# CPSW0_NUSS_ALE register map
Vendor: Texas Instruments
Peripheral module from a debugger description file (folder J7VCL).
Registers are 32-bit, read-write, reset values left out (the file's numbers can be read two ways) unless marked. A register's access mark holds for its fields unless they carry their own. Offsets are as the file gives them; lines under a group give offsets from that group; [hi:lo] are bit positions; {n}, {i} and the like mark numbered series; 'fields as' and 'values as' point back to an identical list; <NAME> marks a mode.

## CPSW0_NUSS_ALE
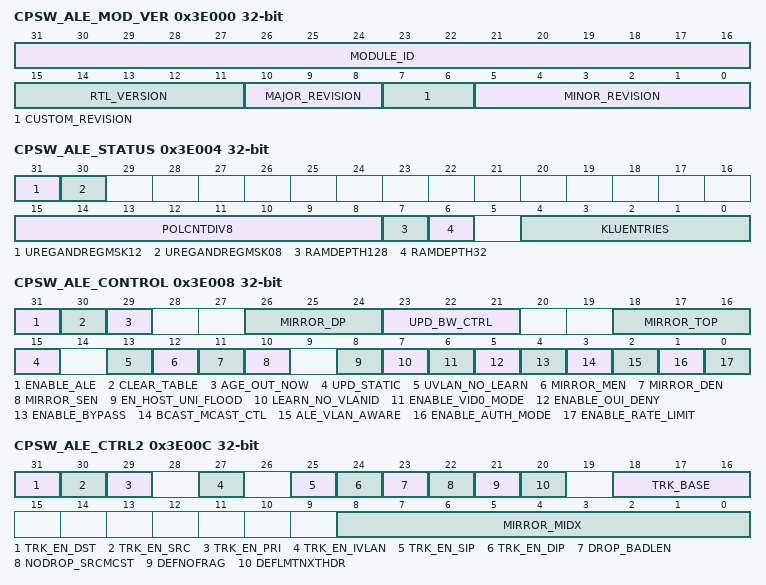
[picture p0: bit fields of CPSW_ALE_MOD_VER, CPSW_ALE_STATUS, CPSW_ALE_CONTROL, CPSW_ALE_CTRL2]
0x3E000 CPSW_ALE_MOD_VER ro — The Module and Version Register identifies the module identifier and revision of the ALE module.
  [31:16] MODULE_ID — ALE module ID.
  [15:11] RTL_VERSION
  [10:8] MAJOR_REVISION
  [7:6] CUSTOM_REVISION
  [5:0] MINOR_REVISION
0x3E004 CPSW_ALE_STATUS ro — The ALE status provides information on the ALE configuration and state. The RAMDEPTH is used to determine how IPv6 entries are stored in the table. IPv6 entries are stored in two entries where IPv6 Entry Hi is designated by the odd slice index and Lo is designated by the even slice index. The slice index is above the ram depth like {SlixeIndex,RamIndex}. So for a 64 deep RAM index of 0x005, the Hi portion of the IPv6 entry is located at 0x005|0x040 and the Lo portion is located at 0x005&(~0x040).
  [31] UREGANDREGMSK12 — When set, the unregistered multicast field is a mask versus an index on 12 bit boundary in the ALE table.
  [30] UREGANDREGMSK08 — When set, the unregistered multicast field is a mask versus an index on 8 bit boundary in the ALE table.
  [15:8] POLCNTDIV8 — This is the number of policer engines the ALE implements divided by 8.
  [7] RAMDEPTH128 — The number of ALE entries per slice of the table when this is set it indicates the depth is 128 if both ramdepth128 and ramdepth32 are zero the depth is 64.
  [6] RAMDEPTH32 — The number of ALE entries per slice of the table when this is set it indicates the depth is 32 if both ramdepth128 and ramdepth32 are zero the depth is 64.
  [4:0] KLUENTRIES — This is the number of table entries total divided by 1024.
0x3E008 CPSW_ALE_CONTROL — The ALE Control Register is used to set the ALE modes used for all ports.
  [31] ENABLE_ALE
  [30] CLEAR_TABLE — Clear ALE address table. Setting this bit causes the ALE hardware to write all table bit values to zero.
  [29] AGE_OUT_NOW — Age Out Address Table Now. Setting this bit causes the ALE hardware to remove (free up) any ageable table entry that does not have a set touch bit.
  [26:24] MIRROR_DP — Mirror Destination Port. This field defines the port to which destination traffic destined will be duplicated.
  [23:21] UPD_BW_CTRL — The UPD_BW_CTRL field allows for up to 8 times the rate in which adds, updates, touches, writes, and aging updates can occur.
  [18:16] MIRROR_TOP — Mirror To Port. This field defines the destination port for the mirror traffic.
  [15] UPD_STATIC — Update Static Entries. A static Entry is an entry that is not agable.
  [13] UVLAN_NO_LEARN — Unknown VLAN No Learn. This field when set will prevent source addresses of unknown VLAN IDs from being automatically added into the look up table if learning is enabled.
  [12] MIRROR_MEN — Mirror Match Entry Enable. This field enables the match mirror option.
  [11] MIRROR_DEN — Mirror Destination Port Enable. This field enables the destination port mirror option.
  [10] MIRROR_SEN — Mirror Source Port Enable. This field enables the source port mirror option.
  [8] EN_HOST_UNI_FLOOD — Unknown unicast packets flood to host.
  [7] LEARN_NO_VLANID — Learn No VID.
  [6] ENABLE_VID0_MODE — Enable VLAN ID = 0 Mode.
  [5] ENABLE_OUI_DENY — Enable OUI Deny Mode. When set, any packet with a non-matching OUI source address will be dropped to the host unless the packet destination address matches a supervisory destination address table entry.
  [4] ENABLE_BYPASS — ALE Bypass. When set, packets received on non-host ports are sent to the host.
  [3] BCAST_MCAST_CTL — Rate Limit Transmit mode.
  [2] ALE_VLAN_AWARE — ALE VLAN Aware. Determines how traffic is forwarded using VLAN rules.
  [1] ENABLE_AUTH_MODE — Enable MAC Authorization Mode. Mac authorization mode requires that all table entries be made by the host software.
  [0] ENABLE_RATE_LIMIT — Enable Broadcast and Multicast Rate Limit
0x3E00C CPSW_ALE_CTRL2 — The ALE Control 2 Register is used to set the extended features used for all ports.
  [31] TRK_EN_DST — Trunk Enable Destination Address. This field enables the destination MAC address to be used with the hash function G(X) = 1 + X + X^3 and affect the trunk port transmit link determination.
  [30] TRK_EN_SRC — Trunk Enable Source Address. This field enables the source MAC address to be used with the hash function G(X) = 1 + X + X^3 and affect the trunk port transmit link determination.
  [29] TRK_EN_PRI — Trunk Enable Priority. This field enables the VLAN Priority bits to be used with the hash function G(X) = 1 + X + X^3 and affect the trunk port transmit link determination.
  [27] TRK_EN_IVLAN — Trunk Enable Inner VLAN. This field enables the inner VLAN ID value (C-VLANID) to be used with the hash function G(X) = 1 + X + X^3 and affect the trunk port transmit link determination.
  [25] TRK_EN_SIP — Trunk Enable Source IP Address. This field enables the source IP address to be used with the hash function G(X) = 1 + X + X^3 and affect the trunk port transmit link determination.
  [24] TRK_EN_DIP — Trunk Enable Destination IP Address. This field enables the destination IP address to be used with the hash function G(X) = 1 + X + X^3 and affect the trunk port transmit link determination.
  [23] DROP_BADLEN — Drop Bad Length will drop any packet that the 802.3 length field is larger than the packet.
  [22] NODROP_SRCMCST — No Drop Source Multicast will disable the dropping of any source address with the multicast bit set.
  [21] DEFNOFRAG — Default No Frag field will cause an IPv4 fragmented packet to be dropped if a VLAN entry is not found.
  [20] DEFLMTNXTHDR — Default limit next header field will cause an IPv4 protocol or IPv6 next header packet to be dropped if a VLAN entry is not found and the protocol or next header does not match the
  [18:16] TRK_BASE — Trunk Base - This field is the hash formula starting value.
  [8:0] MIRROR_MIDX — Mirror Index. This field is the ALE lookup table entry index that when a match occurs will cause this traffic to be mirrored to the MIRROR_TOP port.
0x3E010 CPSW_ALE_PRESCALE — The ALE Prescale Register is used to set the Broadcast and Multicast rate limiting prescaler value.
  [19:0] ALE_PRESCALE — ALE Prescale. The input clock is divided by this value for use in the multicast/broadcast rate limiters.
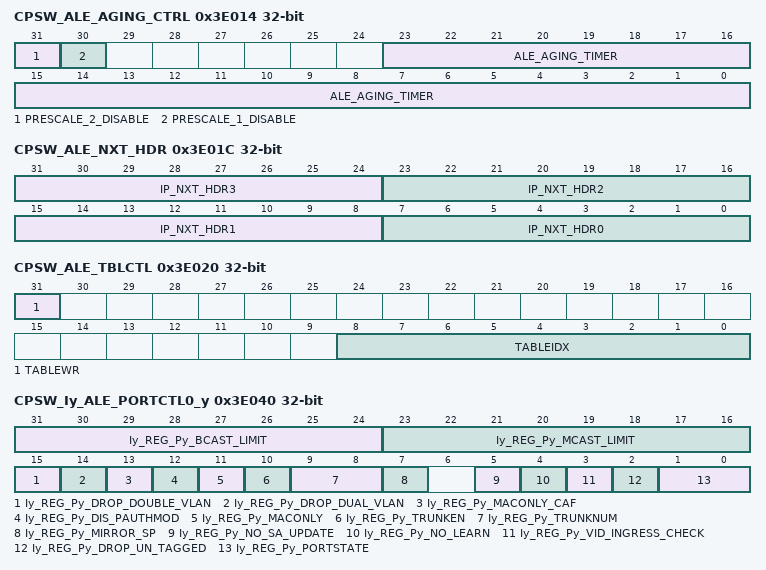
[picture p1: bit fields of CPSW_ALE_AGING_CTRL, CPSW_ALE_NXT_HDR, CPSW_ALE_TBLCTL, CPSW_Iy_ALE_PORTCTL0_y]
0x3E014 CPSW_ALE_AGING_CTRL — The ALE Aging Control sets the aging interval which will cause periodic aging to occur. This value specifies the minimum time between aging starts.
  [31] PRESCALE_2_DISABLE — ALE Prescaler 2 Disable. When set will divide the aging interval by 1000. This bit is designed for device verification and should not be used in production software. Combination of PreScale1Disable and PreScale2Disable will divide the aging interval by 1,000,000 for test purposes.
  [30] PRESCALE_1_DISABLE — ALE Prescaler 1 Disable. When set will divide the aging interval by 1000. This bit is designed for device verification and should not be used in production software. Combination of PreScale1Disable and PreScale2Disable will divide the aging interval by 1,000,000 for test purposes.
  [23:0] ALE_AGING_TIMER
0x3E01C CPSW_ALE_NXT_HDR — The ALE Next Header is used to limit the IPv6 Next header or IPv4 Protocol values found in the IP header. It is enabled via the DEFLMTNXTHDR bit in the VLAN entry. All four IP_NXT_HDR0 to IP_NXT_HDR3 bits are compared when enabled, so if only one is required, set them all to the one value to be tested.
  [31:24] IP_NXT_HDR3 — The IP_NXT_HDR3 is the forth protocol or next header compared when enabled.
  [23:16] IP_NXT_HDR2 — The IP_NXT_HDR2 is the third protocol or next header compared when enabled.
  [15:8] IP_NXT_HDR1 — The IP_NXT_HDR1 is the second protocol or next header compared when enabled.
  [7:0] IP_NXT_HDR0 — The IP_NXT_HDR0 is the first protocol or next header compared when enabled.
0x3E020 CPSW_ALE_TBLCTL — The ALE table control register is used to read or write that ALE table entries. After writing to this register any read or write to any ALE register will be stalled until the read or write operation completes.
  [31] TABLEWR — Table Write. This bit is used to write the table words to the lookup table.
  [8:0] TABLEIDX — The table index is used to determine which lookup table entry is read or written.
0x3E034 CPSW_ALE_TBLW2 — The ALE Table Word 2 is the most significant word of an ALE table entry.
  [6:0] TABLEWRD2 — Table Entry bits [71:64]
0x3E038 CPSW_ALE_TBLW1 — The ALE Table Word 1 is the middle word of an ALE table entry.
  [31:0] TABLEWRD1 — Table Entry bits [63:32].
0x3E03C CPSW_ALE_TBLW0 — The ALE Table Word 0 is the least significant word of an ALE table entry.
  [31:0] TABLEWRD0 — Table Entry bits [31:0].
0x3E040 CPSW_Iy_ALE_PORTCTL0_y — The ALE Port Control Register sets the port specific modes of operation. Offset = 0003E040h + (y * 4h); where y = 0h to 4h
  [31:24] Iy_REG_Py_BCAST_LIMIT — Broadcast Packet Rate Limit. Each prescale pulse loads this field into the port broadcast rate limit counter.
  [23:16] Iy_REG_Py_MCAST_LIMIT — Multicast Packet Rate Limit. Each prescale pulse loads this field into the port multicast rate limit counter.
  [15] Iy_REG_Py_DROP_DOUBLE_VLAN — Drop Double VLAN. When set cause any received packet with double VLANs to be dropped.
  [14] Iy_REG_Py_DROP_DUAL_VLAN — Drop Dual VLAN. When set will cause any received packet with dual VLAN stag followed by ctag to be dropped.
  [13] Iy_REG_Py_MACONLY_CAF — Mac Only Copy All Frames. When set a Mac Only port will transfer all received good frames to the host.
  [12] Iy_REG_Py_DIS_PAUTHMOD — Disable Port authorization. When set will allow unknown addresses to arrive on a switch in authorization mode.
  [11] Iy_REG_Py_MACONLY — MAC Only. When set enables this port be treated like a MAC port for the host.
  [10] Iy_REG_Py_TRUNKEN — Trunk Enable. This field is used to enable a port into a trunk.
  [9:8] Iy_REG_Py_TRUNKNUM — Trunk Number. This field is used as the trunk number when the Iy_REG_Py_TRUNKEN is also set.
  [7] Iy_REG_Py_MIRROR_SP — Mirror Source Port. This field enables the source port mirror option.
  [5] Iy_REG_Py_NO_SA_UPDATE — No Source Address Update. When set will not update the source addresses for this port.
  [4] Iy_REG_Py_NO_LEARN — No Learn. When set will not learn the source addresses for this port.
  [3] Iy_REG_Py_VID_INGRESS_CHECK — VLAN Ingress Check. When set if a packet received is not a member of the VLAN, the packet will be dropped.
  [2] Iy_REG_Py_DROP_UN_TAGGED — If Drop Untagged. When set will drop packets without a VLAN tag.
  [1:0] Iy_REG_Py_PORTSTATE — Port State. Defins the current port state used for lookup operations.
0x3E090 CPSW_ALE_UVLAN_MEMBER — The ALE Unknown VLAN Member Mask Register is used to specify the member list for unknown VLAN ID.
  [4:0] UVLAN_MEMBER_LIST — Unknown VLAN Member List.
0x3E094 CPSW_ALE_UVLAN_URCAST — The ALE Unknown VLAN Unregistered Multicast Flood Mask Register is used to specify which egress ports unregistered multicast addresses egress for the unregistered VLAN ID.
  [4:0] UVLAN_UNREG_MCAST_FLOOD_MASK — Unknown VLAN Unregister Multicast Flood Mask.
0x3E098 CPSW_ALE_UVLAN_RMCAST — The ALE Unknown VLAN Registered Multicast Flood Mask Register is used to specify which egress ports registered multicast addresses egress for the unregistered VLAN ID.
  [4:0] UVLAN_REG_MCAST_FLOOD_MASK — Unknown VLAN Register Multicast Flood Mask. Each bit represents the port to which registered multicast are sent for unregistered VLANs.
0x3E09C CPSW_ALE_UVLAN_UNTAG — The ALE Unknown VLAN force Untagged Egress Mask Register is used to specify which egress ports the VLAN ID will be removed.
  [4:0] UVLAN_FORCE_UNTAGGED_EGRESS — Unknown VLAN Force Untagged Egress Mask. Each bit represents the port where the VLAN will be removed for unregistered VLANs.
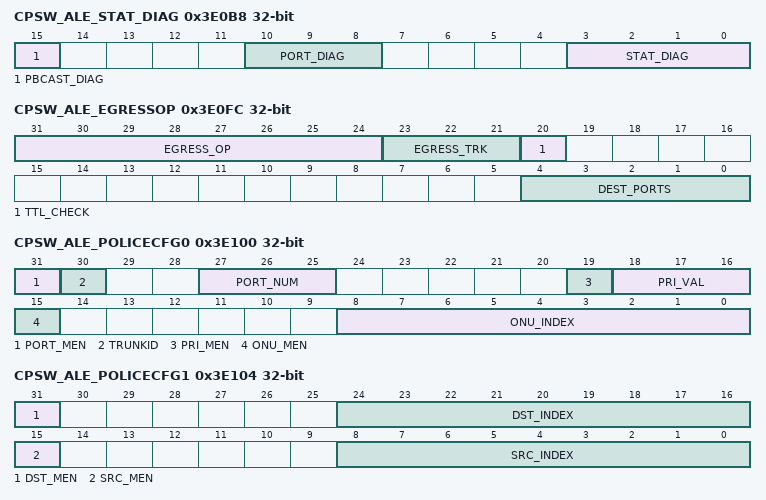
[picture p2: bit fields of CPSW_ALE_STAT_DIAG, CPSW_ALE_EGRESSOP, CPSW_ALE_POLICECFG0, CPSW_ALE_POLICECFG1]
0x3E0B8 CPSW_ALE_STAT_DIAG — The ALE Statistic Output Diagnostic Register allows the output statistics to diagnose the SW counters. This register is for diagnostice only.
  [15] PBCAST_DIAG — When set and the PORT_DIAG is set to zero, will allow all ports to see the same stat diagnostic increment.
  [10:8] PORT_DIAG — The port selected that a received packet will cause the selected error to increment.
  [3:0] STAT_DIAG — When non-zero will cause the selected statistic to increment on the next frame received.
0x3E0BC CPSW_ALE_OAM_LB_CTRL — The ALE OAM Control allows ports to be put into OAM Loopback, only non-supervisor packet are looped back to the source port.
  [4:0] OAM_LB_CTRL — The OAM_LB_CTRL bit field allows any port to be put into OAM loopback, that is any packet received will be returned to the same port with an
0x3E0FC CPSW_ALE_EGRESSOP — The Egress Operation register allows enabled classifiers with IPSA or IPDA match to use the CPSW Egress Packet Operations Inter VLAN Routing sub functions. If the packet was destined for the host, but matches a clasifier that has a programmed egress opcode, it will be forwarded to the destination ports where the destination ports will use the thier egress opcode entry to modify the packet. InterVLAN Routing and mirroring need to be understood, they are orthogonal functions.
  [31:24] EGRESS_OP — The Egress Operation defines the operation performed by the CPSW Egress Packet Operations 0h = NOP : 1-n: Defines which egress Operation will be performed. This allows Inter VLAN routing to be configured for high bandwidth traffic, reducing CPU load. FFh: Swaps source address (SA) and destination address (DA) of packet, this is intended to allow OAM diagnostics for a link.
  [23:21] EGRESS_TRK — The Egress Trunk Index is the calculated trunk index from the SA, DA or VLAN if modified to that InterVLAN routing will work on trunks as well.
  [20] TTL_CHECK — The TTL Check will cause any packet that fails TTL checks to not be routed to the Inter VLAN Routing sub functions.
  [4:0] DEST_PORTS — The Destination Ports is a list of the ports the classified packet will be set to.
0x3E100 CPSW_ALE_POLICECFG0 — The Policing Config 0 holds the port, frame priority and ONU address index as well as match enables for port, frame priority and ONU address matching.
  [31] PORT_MEN — Port Match Enable.
  [30] TRUNKID
  [27:25] PORT_NUM — Port Number.
  [19] PRI_MEN — Priority Match Enable.
  [18:16] PRI_VAL — Priority Value.
  [15] ONU_MEN — OUI Match Enable.
  [8:0] ONU_INDEX — OUI Table Entry Index.
0x3E104 CPSW_ALE_POLICECFG1 — The Policing Config 1 holds the match enable/match index for the L2 Destination and L2 source addresses.
  [31] DST_MEN — Destination Address Match Enable - Enables frame L2 destination address match for the selected policing/classifier entry
  [24:16] DST_INDEX — Destination Address Table Entry Index - Specifies the ALE L2 destination address lookup table index to match for the selected policing/classifier entry
  [15] SRC_MEN — Source Address Match Enable - Enables frame L2 source address match for the selected policing/classifier entry
  [8:0] SRC_INDEX — Source Address Table Entry Index - Specifies the ALE L2 source address lookup table index to match for the selected policing/classifier entry
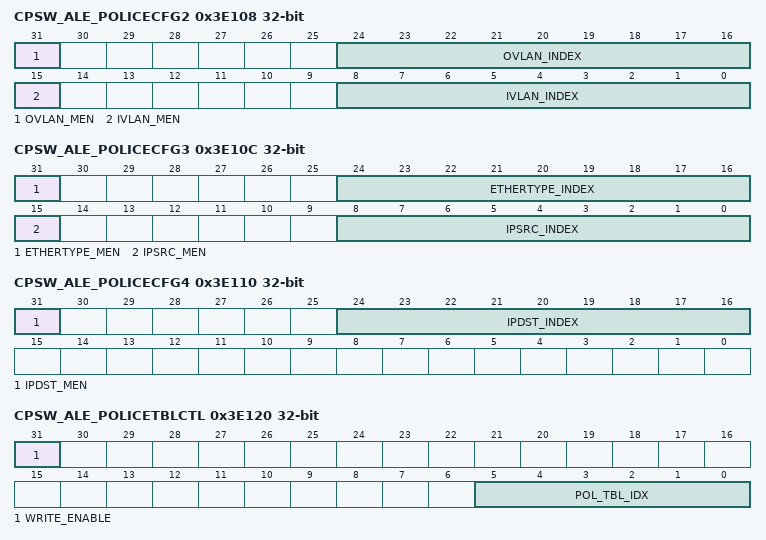
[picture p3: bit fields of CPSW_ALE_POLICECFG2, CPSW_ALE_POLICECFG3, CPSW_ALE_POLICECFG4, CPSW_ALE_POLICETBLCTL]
0x3E108 CPSW_ALE_POLICECFG2 — The Policing Config 2 holds the match enable/match index for the Outer VLAN and Inner VLAN addresses.
  [31] OVLAN_MEN — Outer VLAN Match Enable.
  [24:16] OVLAN_INDEX — Outer VLAN Table Entry Index.
  [15] IVLAN_MEN — Inner VLAN Match Enable.
  [8:0] IVLAN_INDEX — Inner VLAN Table Entry Index.
0x3E10C CPSW_ALE_POLICECFG3 — The Policing Config 3 holds the match enable/match index for the Ether Type and IP Source address.
  [31] ETHERTYPE_MEN — EtherType Match Enable.
  [24:16] ETHERTYPE_INDEX — EtherType Table Entry Index.
  [15] IPSRC_MEN — IP Source Address Match Enable.
  [8:0] IPSRC_INDEX — IP Source Address Table Entry Index.
0x3E110 CPSW_ALE_POLICECFG4 — The Policing Config 4 holds the match enable/match index for the IP Destination address.
  [31] IPDST_MEN — IP Destination Address Match Enable.
  [24:16] IPDST_INDEX — IP Destination Address Table Entry Index.
0x3E118 CPSW_ALE_POLICECFG6 — The PIR counter is a 37-bit internal counter where PIR_IDLE_INC_VAL is added every clock and the frame size << 18 is subtracted at EOF if not RED at LUT time. If the counter is negative the packet will be marked RED, else it can be YELLOW or GREEN based on the CIR counter. If only this counter is used (CIR_IDLE_INC_VAL = 0h), then packets are marked RED or GREEN based on PIR counter only.
  [31:0] PIR_IDLE_INC_VAL — Peak Information Rate Idle Increment Value.
0x3E11C CPSW_ALE_POLICECFG7 — The CIR counter is a 37-bit internal counter where CIR_IDLE_INC_VAL is added every clock and the frame size << 18 is subtracted at EOF if not RED or YELLOW at LUT time. If the counter is positive the packet will be marked GREEN, else it can be YELLOW or RED based on the PIR counter. If only this counter is used (PIR_IDLE_INC_VAL= 0h), then packets are marked YELLOW or GREEN based on CIR counter only.
  [31:0] CIR_IDLE_INC_VAL — Committed Information Idle Increment Value.
0x3E120 CPSW_ALE_POLICETBLCTL — The Policing Table Control is used to read or write the selected policing/classifier entry. The selected policing/classifier entry is only read or written after this register is written based on the value of the WRITE_ENABLE bit.
  [31] WRITE_ENABLE — Write Enable - Setting this bit will write the
  [5:0] POL_TBL_IDX — Policer Entry Index - This field specifies the policing/classifier entry to be read or written.
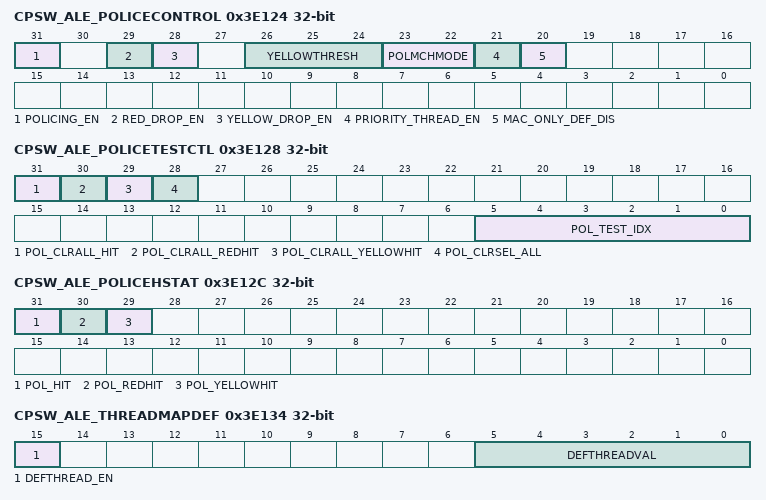
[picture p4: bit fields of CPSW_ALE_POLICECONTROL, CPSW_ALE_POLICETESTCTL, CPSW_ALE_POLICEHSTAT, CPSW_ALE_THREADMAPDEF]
0x3E124 CPSW_ALE_POLICECONTROL — The Control Enables color marking as well as internal ALE packet dropping rules.
  [31] POLICING_EN — Policing Enable.
  [29] RED_DROP_EN — RED Drop Enable.
  [28] YELLOW_DROP_EN — WELLOW Drop Enable.
  [26:24] YELLOWTHRESH — Yellow Threshold.
  [23:22] POLMCHMODE — Policing Match Mode.
  [21] PRIORITY_THREAD_EN — Priority Thread Enable.
  [20] MAC_ONLY_DEF_DIS — MAC Only Default Disable.
0x3E128 CPSW_ALE_POLICETESTCTL — The Policing Test Control enables the ability to determine which policing entry has been hit and whether they reported a red or yellow rate condition.
  [31] POL_CLRALL_HIT — Policer Clear. This bit clears all the policing/ classifier hit bits.
  [30] POL_CLRALL_REDHIT — Policer Clear RED. This bit clears all the policing/ classifier RED hit bits.
  [29] POL_CLRALL_YELLOWHIT — Policer Clear YELLOW. This bit clears all the policing/ classifier YELLOW hit bits.
  [28] POL_CLRSEL_ALL — Police Clear Selected. This bit clears the selected policing/ classifier hit, redhit and yellowhit bits.
  [5:0] POL_TEST_IDX — Policer Test Index. This field selects which policing/ classifier hit bits will be read or written.
0x3E12C CPSW_ALE_POLICEHSTAT ro — The policing hit status is a read only register that reads the hit bits of the selected policing/classifier.
  [31] POL_HIT — Policer Hit.
  [30] POL_REDHIT — Policer Hit RED.
  [29] POL_YELLOWHIT — Policer Hit YELLOW.
0x3E134 CPSW_ALE_THREADMAPDEF — The THREAD Mapping Default Value register is used to set the default thread ID when no classifier is matched.
  [15] DEFTHREAD_EN — Default Tread Enable.
  [5:0] DEFTHREADVAL — Default Thread Value.
0x3E138 CPSW_ALE_THREADMAPCTL — The THREAD Mapping Control register allows the highest matched classifier to return a particular thread ID for traffic sent to the host. This allows particular classifier matched traffic to be placed an a particular hosts queue.
  [5:0] CLASSINDEX — Classifier Index - This is the classifier index entry that the thread enable and thread value will be read or written by the Classifier Index.
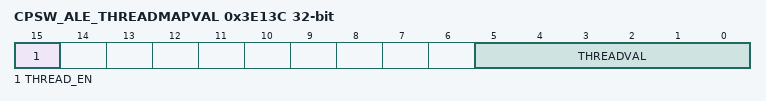
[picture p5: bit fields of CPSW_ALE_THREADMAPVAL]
0x3E13C CPSW_ALE_THREADMAPVAL — The THREAD Mapping Value register is used to set the thread ID for a particular classifier entry.
  [15] THREAD_EN — Thread Enable.
  [5:0] THREADVAL — Thread Value.
